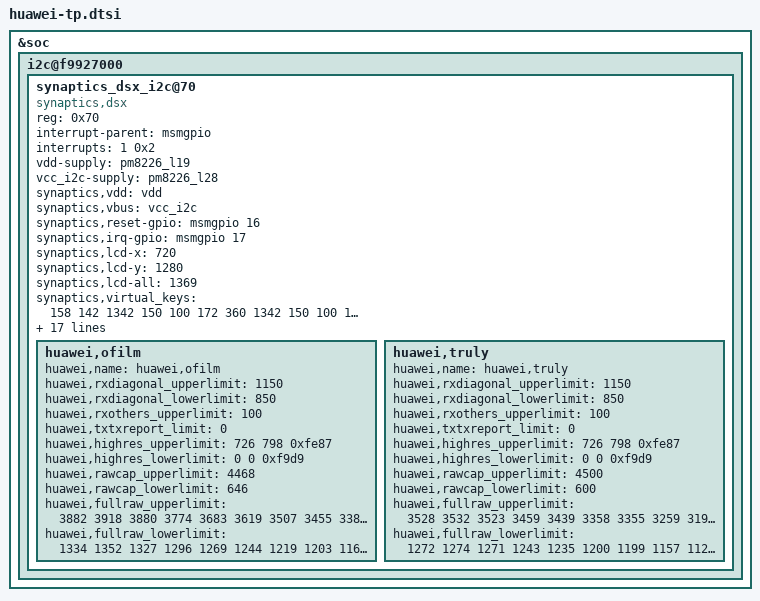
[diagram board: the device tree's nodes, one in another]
/*Add synaptics new driver "Synaptics DSX I2C V2.0"*/
&soc{
	i2c@f9927000 {
		status = "ok";
		synaptics_dsx_i2c@70 {
			compatible = "synaptics,dsx";
			reg = <0x70>;
			interrupt-parent = <&msmgpio>;
			interrupts = <1 0x2>;
			vdd-supply = <&pm8226_l19>;
			vcc_i2c-supply = <&pm8226_l28>;
			synaptics,vdd = "vdd";
			synaptics,vbus = "vcc_i2c";
			synaptics,reset-gpio = <&msmgpio 16 0x00>;
			synaptics,irq-gpio = <&msmgpio 17 0x00>;

			synaptics,lcd-x = <720>;
			synaptics,lcd-y = <1280>;
			synaptics,lcd-all = <1369>;
			synaptics,virtual_keys = /* KeyCode CenterX CenterY Width Height */
				/* KEY_BACK */
				<158 142 1342 150 100
				/* KEY_HOMEPAGE instead of KEY_HOME(102) */
				172 360 1342 150 100
				/* KEY_MENU */
				139 578 1342 150 100>;

			/* SYNAPTICS_WAKE_UP_GESTURE_FLAG:'1'->enabled,'0'->disabled */
			/*IC flash is not enough for holster,so del one gesture*/
			synaptics,gesture_enabled = <0>;
			/* Gestures that supported:                           */
			/* bit0  Double tap                                        */
			/* bit1  Single finger slide from left to right     */
			/* bit2  Single finger slide from right to left     */
			/* bit3  Single finger slide from top to bottom  */
			/* bit4  Single finger slide from bottom to top  */
			/* bit5  Double finger slide from top to bottom--disable for holster*/
			/* bit6  Single finger slide circle                     */
			/* bit7  Single finger write letter c                  */
			/* bit8  Single finger write letter e                  */
			/* bit9  Single finger write letter m                 */
			/* bit10 Single finger write letter w                 */
			/* bit11 Palm off screen                                */
			synaptics,easy_wakeup_supported_gestures = <0xFDF>;

			/*Defination of report key value  for different gestures*/
			synaptics,easy_wakeup_gesture_keys = 
			<	59 /*0.Double tap:KEY_F1*/
				60 /*1.Single finger slide from left to right*/
				61 /*2.Single finger slide from right to left:KEY_F3*/
				62 /*3.Single finger slide from top to bottom*/
				63 /*4.Single finger slide from bottom to top:KEY_F5*/
				64 /*5.Double finger slide from top to bottom*/
				65 /*6.Single finger slide circle:KEY_F7*/
				66 /*7.Single finger write letter c*/
				67 /*8.Single finger write letter e:KEY_F9*/
				68 /*9.Single finger write letter m*/
				87 /*10.Single finger write letter w:KEY_F11*/
				88 /*11.Palm off screen*/
			>;

			/* Double-tap-zone defined by huawei */
			/* Shielded area is:1cm left,1cm right,3cm up,2cm down */
			huawei,dtz_x0 = <116>;
			huawei,dtz_y0 = <349>;
			huawei,dtz_x1 = <604>;
			huawei,dtz_y1 = <1047>;

			/* SYNAPTICS_GLOVE_FUNCTION_FLAG:'1'->enabled,'0'->disabled*/
			synaptics,glove_enabled = <0>;
			/*After reduce power-consumption by exit reduce mode,*/
			/*we have to reduce f-r rate to make sure gesture work fine*/
			synaptics,fast_relax_gesture = <7>;
			/*Holster support flag*/
			synaptics,holster_supported = <1>;

			synaptics,reset-on-status = <0>;
			synaptics,power-delay-ms = <160>;
			synaptics,reset-delay-ms = <100>;
			synaptics,reset-active-ms = <90>;
			synaptics,product_name = "g660L";

			/*capacitance self-adapt*/
			huawei,ofilm {
				huawei,name = "huawei,ofilm";
				huawei,rxdiagonal_upperlimit = <1150>;
				huawei,rxdiagonal_lowerlimit = <850>;
				huawei,rxothers_upperlimit = <100>;
				huawei,txtxreport_limit = <0>;
				huawei,highres_upperlimit = <726 798 0xfe87>;/*0xfe87==-377*/
				huawei,highres_lowerlimit = <0 0 0xf9d9>;/*0xf9d9==-1575*/
				huawei,rawcap_upperlimit = <4468>;
				huawei,rawcap_lowerlimit = <646>;

				huawei,fullraw_upperlimit =
					<3882 3918 3880 3774 3683 3619 3507 3455 3385 3312 3292 3197 4037 3977 3910 3885 3836 3827 3792 3771 3752 3705 3689 2702 
					4050 4141 4093 3985 3894 3823 3724 3665 3598 3500 3441 3358 3914 3920 3868 3802 3801 3794 3760 3759 3736 3707 3687 3627 
					4072 4162 4110 4001 3908 3843 3745 3684 3619 3522 3460 3378 3830 3831 3770 3710 3714 3687 3663 3656 3637 3621 3591 3616 
					4085 4177 4124 4016 3929 3855 3785 3705 3644 3540 3479 3392 3752 3757 3672 3631 3619 3592 3570 3563 3540 3530 3495 3549 
					4107 4201 4144 4034 3959 3875 3787 3732 3670 3567 3504 3424 3675 3689 3595 3557 3542 3516 3484 3486 3452 3430 3409 3473 
					4111 4226 4166 4069 3999 3899 3808 3756 3697 3606 3542 3466 3603 3621 3528 3477 3463 3441 3406 3402 3379 3355 3325 3397 
					4159 4257 4204 4107 4025 3936 3859 3801 3732 3654 3584 3515 3550 3582 3472 3410 3404 3374 3343 3332 3315 3301 3264 3330 
					4191 4293 4239 4141 4074 3983 3914 3840 3785 3711 3640 3584 3491 3533 3423 3353 3343 3325 3278 3280 3255 3222 3207 3292 
					4230 4340 4275 4180 4139 4060 3966 3907 3840 3760 3700 3658 3444 3495 3385 3302 3299 3287 3232 3232 3201 3169 3155 3248 
					4261 4382 4316 4222 4180 4103 4022 3966 3889 3851 3777 3728 3416 3470 3357 3269 3263 3257 3199 3190 3165 3130 3115 3235 
					4299 4431 4359 4274 4235 4163 4095 4036 3963 3932 3850 3819 3382 3445 3329 3249 3236 3221 3162 3161 3144 3096 3080 3207 
					4334 4464 4415 4338 4302 4240 4162 4113 4033 4016 3936 3913 3354 3423 3308 3224 3213 3200 3134 3130 3113 3068 3098 3486 
					4278 4422 4356 4306 4256 4197 4125 4095 4025 3971 3934 3894 3193 3218 3185 3147 3106 3129 3077 3060 3022 3032 3010 2072>;

				huawei,fullraw_lowerlimit =
					<1334 1352 1327 1296 1269 1244 1219 1203 1168 1155 1125 1100 1308 1298 1283 1281 1280 1264 1251 1251 1240 1232 1225 764 
					1336 1370 1348 1317 1283 1262 1235 1221 1183 1172 1141 1117 1230 1221 1216 1215 1198 1185 1175 1182 1164 1157 1164 1241 
					1274 1373 1350 1313 1283 1259 1235 1217 1178 1169 1136 1111 1198 1194 1188 1181 1161 1149 1139 1151 1127 1118 1125 1163 
					1363 1371 1360 1326 1293 1268 1245 1226 1194 1176 1150 1125 1184 1176 1172 1166 1150 1137 1124 1130 1116 1106 1110 1149 
					1358 1383 1365 1331 1299 1276 1254 1236 1191 1185 1149 1125 1156 1156 1149 1137 1116 1101 1091 1105 1080 1072 1074 1110 
					1344 1379 1364 1331 1296 1272 1247 1229 1191 1180 1148 1125 1133 1130 1125 1113 1093 1076 1064 1079 1054 1043 1043 1076 
					1301 1364 1355 1339 1307 1280 1256 1236 1214 1189 1164 1152 1127 1120 1116 1109 1102 1089 1073 1062 1061 1054 1053 1075 
					1317 1403 1380 1349 1311 1286 1261 1247 1220 1196 1173 1161 1113 1107 1101 1094 1086 1071 1056 1046 1043 1034 1032 1065 
					1400 1410 1392 1358 1323 1298 1270 1251 1226 1204 1184 1171 1104 1097 1091 1083 1075 1067 1049 1031 1028 1028 1021 1058 
					1415 1413 1399 1367 1337 1308 1283 1270 1243 1218 1147 1074 978  986  965  971  950  944  921  937  926  909  906  932  
					1423 1430 1409 1376 1346 1319 1296 1279 1252 1233 1209 1199 1088 1079 1073 1064 1057 1050 1031 1013 1012 1010 1001 1046 
					1424 1438 1422 1391 1359 1339 1314 1300 1275 1252 1231 1221 1087 1076 1073 1064 1053 1048 1031 1011 1008 1008 1001 1118 
					1444 1467 1454 1437 1411 1393 1373 1356 1327 1308 1286 1280 1069 1058 1052 1044 1034 1030 1013 993  990  990  897  645>;
			};
			huawei,truly {
				huawei,name = "huawei,truly";
				huawei,rxdiagonal_upperlimit = <1150>;
				huawei,rxdiagonal_lowerlimit = <850>;
				huawei,rxothers_upperlimit = <100>;
				huawei,txtxreport_limit = <0>;
				huawei,highres_upperlimit = <726 798 0xfe87>;/*0xfe87==-377*/
				huawei,highres_lowerlimit = <0 0 0xf9d9>;/*0xf9d9==-1575*/
				huawei,rawcap_upperlimit = <4500>;
				huawei,rawcap_lowerlimit = <600>;

				huawei,fullraw_upperlimit =
					<3528 3532 3523 3459 3439 3358 3355 3259 3192 3158 3155 3032 3670 3638 3589 3592 3593 3582 3553 3532 3459 3490 3474 2508 
					3598 3607 3609 3540 3518 3430 3420 3337 3263 3236 3229 3096 3445 3431 3410 3407 3407 3396 3368 3351 3278 3319 3301 3477 
					3592 3620 3613 3556 3526 3438 3431 3343 3267 3246 3236 3105 3389 3365 3357 3344 3348 3326 3301 3283 3211 3246 3232 3221 
					3616 3648 3635 3575 3544 3459 3458 3367 3290 3266 3255 3133 3353 3333 3318 3306 3319 3301 3269 3248 3179 3211 3196 3214 
					3617 3654 3644 3581 3547 3465 3473 3378 3305 3290 3277 3150 3311 3284 3276 3264 3274 3262 3228 3204 3129 3171 3154 3148 
					3630 3672 3652 3592 3567 3484 3488 3390 3330 3299 3291 3168 3259 3238 3232 3215 3227 3213 3173 3157 3073 3116 3106 3087 
					3661 3700 3677 3619 3598 3514 3502 3423 3364 3332 3323 3208 3222 3206 3203 3180 3192 3172 3137 3120 3036 3074 3073 3022 
					3673 3722 3717 3658 3627 3553 3543 3462 3392 3360 3357 3248 3204 3185 3173 3159 3171 3150 3109 3092 3007 3050 3042 3019 
					3698 3735 3729 3676 3640 3567 3561 3488 3427 3388 3376 3271 3171 3147 3137 3126 3126 3105 3071 3054 2973 3010 2994 2987 
					3728 3764 3757 3704 3677 3614 3602 3532 3474 3439 3425 3325 3161 3141 3123 3103 3109 3085 3052 3035 2961 2987 2970 2977 
					3747 3799 3791 3743 3724 3649 3638 3572 3529 3500 3490 3378 3152 3136 3123 3095 3106 3082 3046 3032 2951 2986 2968 2952 
					3763 3827 3809 3767 3747 3675 3675 3607 3558 3530 3518 3427 3123 3105 3081 3068 3068 3052 3007 2993 2912 2945 2938 3199 
					3826 3886 3865 3841 3826 3778 3778 3725 3670 3649 3630 3550 3059 3029 3024 3005 3008 2984 2949 2933 2850 2879 2860 1939>;

				huawei,fullraw_lowerlimit =
					<1272 1274 1271 1243 1235 1200 1199 1157 1128 1114 1113 1060 1334 1320 1299 1300 1301 1296 1283 1274 1243 1256 1250 836 
					1302 1307 1307 1278 1268 1230 1226 1191 1159 1148 1145 1088 1237 1231 1222 1221 1221 1216 1204 1197 1166 1183 1175 1251
					1300 1312 1309 1284 1272 1234 1231 1193 1161 1152 1148 1091 1213 1203 1199 1194 1196 1186 1175 1167 1137 1152 1146 1141
					1310 1324 1319 1293 1280 1243 1242 1203 1170 1160 1155 1103 1197 1189 1182 1178 1183 1175 1161 1152 1123 1137 1130 1138
					1311 1326 1322 1295 1281 1245 1249 1208 1177 1170 1165 1110 1179 1168 1164 1160 1164 1158 1144 1134 1101 1119 1112 1110
					1316 1334 1326 1300 1289 1254 1256 1214 1188 1175 1171 1118 1157 1148 1146 1139 1143 1137 1121 1113 1077 1096 1092 1083
					1329 1346 1337 1311 1302 1266 1262 1227 1202 1188 1185 1136 1142 1134 1133 1124 1128 1120 1105 1098 1062 1078 1077 1056
					1335 1356 1353 1328 1315 1283 1279 1244 1214 1200 1199 1152 1134 1125 1121 1115 1119 1110 1093 1086 1049 1068 1064 1055
					1346 1361 1359 1336 1320 1289 1287 1256 1229 1212 1208 1163 1119 1109 1105 1100 1100 1091 1077 1070 1035 1050 1044 1041
					1358 1374 1371 1348 1337 1310 1304 1274 1250 1235 1229 1185 1115 1107 1099 1091 1093 1083 1068 1061 1029 1041 1034 1037
					1367 1389 1385 1365 1356 1325 1320 1292 1273 1260 1256 1208 1112 1104 1099 1087 1092 1082 1066 1060 1025 1040 1032 1026
					1373 1401 1393 1375 1367 1335 1335 1307 1286 1274 1268 1229 1099 1091 1081 1076 1076 1068 1049 1043 1008 1023 1020 1131
					1400 1426 1417 1407 1400 1380 1380 1357 1334 1325 1316 1282 1071 1059 1056 1049 1050 1040 1025 1017 982 995 986 591>;
			};
		};
	};
};

